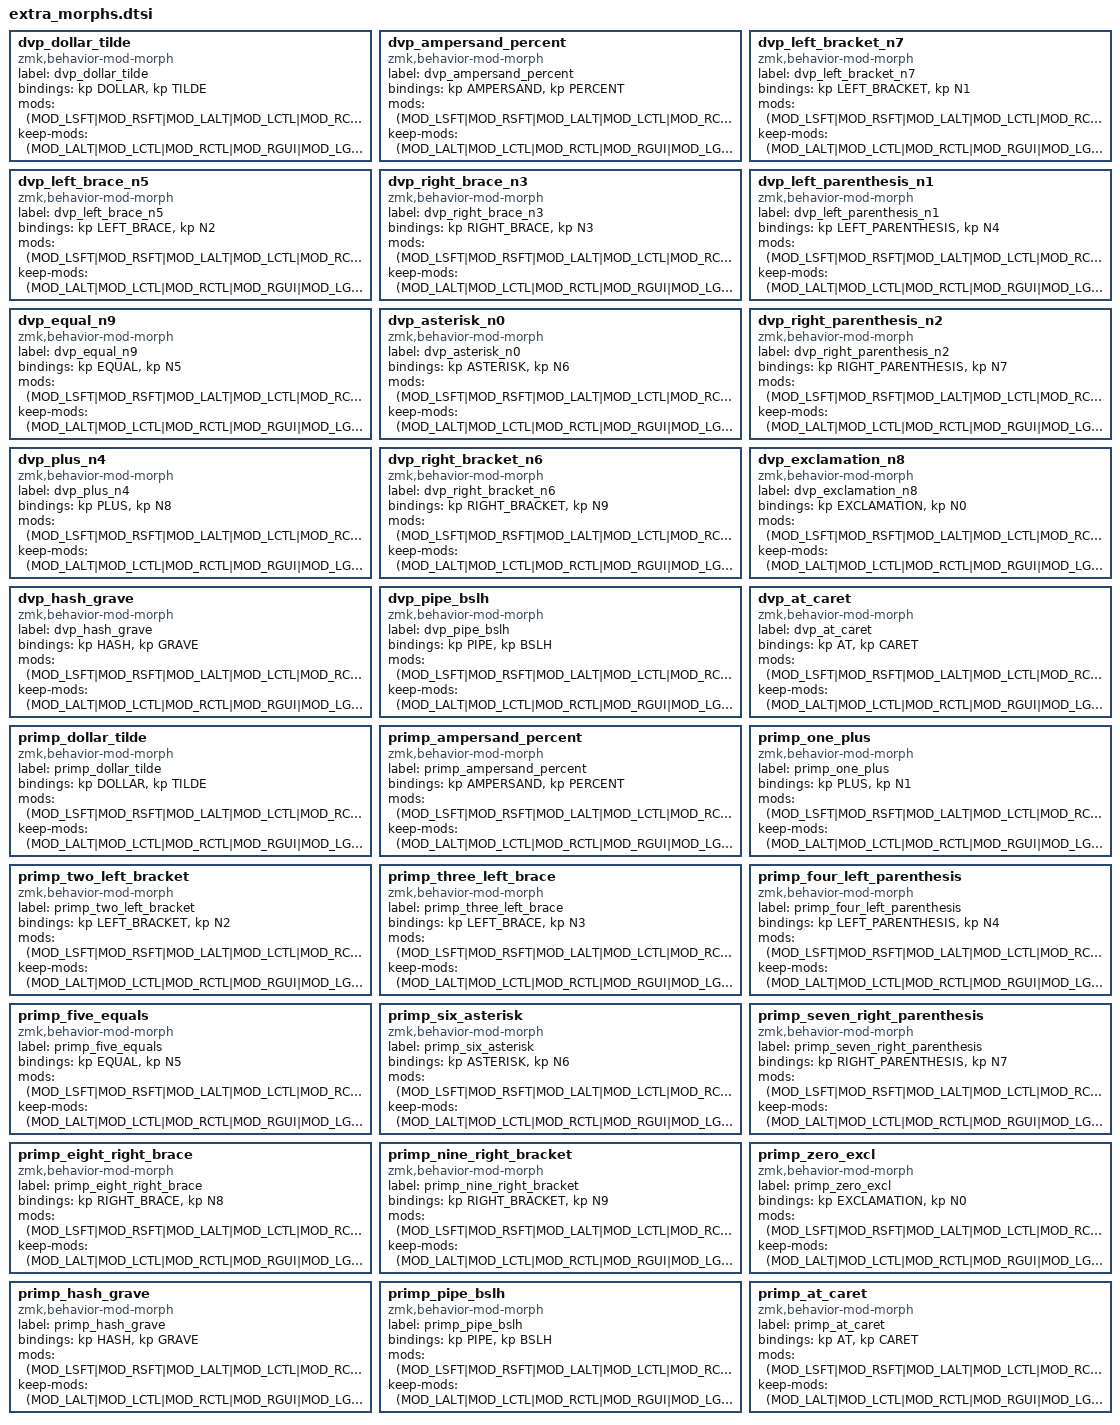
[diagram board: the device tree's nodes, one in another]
dvp_dollar_tilde: dvp_dollar_tilde {
    compatible = "zmk,behavior-mod-morph";
    label = "dvp_dollar_tilde";
    #binding-cells = <0>;
    bindings = <&kp DOLLAR>, <&kp TILDE>;
    mods = <(MOD_LSFT|MOD_RSFT|MOD_LALT|MOD_LCTL|MOD_RCTL|MOD_RGUI|MOD_LGUI)>;
    keep-mods = <(MOD_LALT|MOD_LCTL|MOD_RCTL|MOD_RGUI|MOD_LGUI)>;
};
dvp_ampersand_percent: dvp_ampersand_percent {
    compatible = "zmk,behavior-mod-morph";
    label = "dvp_ampersand_percent";
    #binding-cells = <0>;
    bindings = <&kp AMPERSAND>, <&kp PERCENT>;
    mods = <(MOD_LSFT|MOD_RSFT|MOD_LALT|MOD_LCTL|MOD_RCTL|MOD_RGUI|MOD_LGUI)>;
    keep-mods = <(MOD_LALT|MOD_LCTL|MOD_RCTL|MOD_RGUI|MOD_LGUI)>;
};
dvp_left_bracket_n7: dvp_left_bracket_n7 {
    compatible = "zmk,behavior-mod-morph";
    label = "dvp_left_bracket_n7";
    #binding-cells = <0>;
    bindings = <&kp LEFT_BRACKET>, <&kp N1>;
    mods = <(MOD_LSFT|MOD_RSFT|MOD_LALT|MOD_LCTL|MOD_RCTL|MOD_RGUI|MOD_LGUI)>;
    keep-mods = <(MOD_LALT|MOD_LCTL|MOD_RCTL|MOD_RGUI|MOD_LGUI)>;
};
dvp_left_brace_n5: dvp_left_brace_n5 {
    compatible = "zmk,behavior-mod-morph";
    label = "dvp_left_brace_n5";
    #binding-cells = <0>;
    bindings = <&kp LEFT_BRACE>, <&kp N2>;
    mods = <(MOD_LSFT|MOD_RSFT|MOD_LALT|MOD_LCTL|MOD_RCTL|MOD_RGUI|MOD_LGUI)>;
    keep-mods = <(MOD_LALT|MOD_LCTL|MOD_RCTL|MOD_RGUI|MOD_LGUI)>;
};
dvp_right_brace_n3: dvp_right_brace_n3 {
    compatible = "zmk,behavior-mod-morph";
    label = "dvp_right_brace_n3";
    #binding-cells = <0>;
    bindings = <&kp RIGHT_BRACE>, <&kp N3>;
    mods = <(MOD_LSFT|MOD_RSFT|MOD_LALT|MOD_LCTL|MOD_RCTL|MOD_RGUI|MOD_LGUI)>;
    keep-mods = <(MOD_LALT|MOD_LCTL|MOD_RCTL|MOD_RGUI|MOD_LGUI)>;
};
dvp_left_parenthesis_n1: dvp_left_parenthesis_n1 {
    compatible = "zmk,behavior-mod-morph";
    label = "dvp_left_parenthesis_n1";
    #binding-cells = <0>;
    bindings = <&kp LEFT_PARENTHESIS>, <&kp N4>;
    mods = <(MOD_LSFT|MOD_RSFT|MOD_LALT|MOD_LCTL|MOD_RCTL|MOD_RGUI|MOD_LGUI)>;
    keep-mods = <(MOD_LALT|MOD_LCTL|MOD_RCTL|MOD_RGUI|MOD_LGUI)>;
};
dvp_equal_n9: dvp_equal_n9 {
    compatible = "zmk,behavior-mod-morph";
    label = "dvp_equal_n9";
    #binding-cells = <0>;
    bindings = <&kp EQUAL>, <&kp N5>;
    mods = <(MOD_LSFT|MOD_RSFT|MOD_LALT|MOD_LCTL|MOD_RCTL|MOD_RGUI|MOD_LGUI)>;
    keep-mods = <(MOD_LALT|MOD_LCTL|MOD_RCTL|MOD_RGUI|MOD_LGUI)>;
};
dvp_asterisk_n0: dvp_asterisk_n0 {
    compatible = "zmk,behavior-mod-morph";
    label = "dvp_asterisk_n0";
    #binding-cells = <0>;
    bindings = <&kp ASTERISK>, <&kp N6>;
    mods = <(MOD_LSFT|MOD_RSFT|MOD_LALT|MOD_LCTL|MOD_RCTL|MOD_RGUI|MOD_LGUI)>;
    keep-mods = <(MOD_LALT|MOD_LCTL|MOD_RCTL|MOD_RGUI|MOD_LGUI)>;
};
dvp_right_parenthesis_n2: dvp_right_parenthesis_n2 {
    compatible = "zmk,behavior-mod-morph";
    label = "dvp_right_parenthesis_n2";
    #binding-cells = <0>;
    bindings = <&kp RIGHT_PARENTHESIS>, <&kp N7>;
    mods = <(MOD_LSFT|MOD_RSFT|MOD_LALT|MOD_LCTL|MOD_RCTL|MOD_RGUI|MOD_LGUI)>;
    keep-mods = <(MOD_LALT|MOD_LCTL|MOD_RCTL|MOD_RGUI|MOD_LGUI)>;
};
dvp_plus_n4: dvp_plus_n4 {
    compatible = "zmk,behavior-mod-morph";
    label = "dvp_plus_n4";
    #binding-cells = <0>;
    bindings = <&kp PLUS>, <&kp N8>;
    mods = <(MOD_LSFT|MOD_RSFT|MOD_LALT|MOD_LCTL|MOD_RCTL|MOD_RGUI|MOD_LGUI)>;
    keep-mods = <(MOD_LALT|MOD_LCTL|MOD_RCTL|MOD_RGUI|MOD_LGUI)>;
};
dvp_right_bracket_n6: dvp_right_bracket_n6 {
    compatible = "zmk,behavior-mod-morph";
    label = "dvp_right_bracket_n6";
    #binding-cells = <0>;
    bindings = <&kp RIGHT_BRACKET>, <&kp N9>;
    mods = <(MOD_LSFT|MOD_RSFT|MOD_LALT|MOD_LCTL|MOD_RCTL|MOD_RGUI|MOD_LGUI)>;
    keep-mods = <(MOD_LALT|MOD_LCTL|MOD_RCTL|MOD_RGUI|MOD_LGUI)>;
};
dvp_exclamation_n8: dvp_exclamation_n8 {
    compatible = "zmk,behavior-mod-morph";
    label = "dvp_exclamation_n8";
    #binding-cells = <0>;
    bindings = <&kp EXCLAMATION>, <&kp N0>;
    mods = <(MOD_LSFT|MOD_RSFT|MOD_LALT|MOD_LCTL|MOD_RCTL|MOD_RGUI|MOD_LGUI)>;
    keep-mods = <(MOD_LALT|MOD_LCTL|MOD_RCTL|MOD_RGUI|MOD_LGUI)>;
};
dvp_hash_grave: dvp_hash_grave {
    compatible = "zmk,behavior-mod-morph";
    label = "dvp_hash_grave";
    #binding-cells = <0>;
    bindings = <&kp HASH>, <&kp GRAVE>;
    mods = <(MOD_LSFT|MOD_RSFT|MOD_LALT|MOD_LCTL|MOD_RCTL|MOD_RGUI|MOD_LGUI)>;
    keep-mods = <(MOD_LALT|MOD_LCTL|MOD_RCTL|MOD_RGUI|MOD_LGUI)>;
};
dvp_pipe_bslh: dvp_pipe_bslh {
    compatible = "zmk,behavior-mod-morph";
    label = "dvp_pipe_bslh";
    #binding-cells = <0>;
    bindings = <&kp PIPE>, <&kp BSLH>;
    mods = <(MOD_LSFT|MOD_RSFT|MOD_LALT|MOD_LCTL|MOD_RCTL|MOD_RGUI|MOD_LGUI)>;
    keep-mods = <(MOD_LALT|MOD_LCTL|MOD_RCTL|MOD_RGUI|MOD_LGUI)>;
};
dvp_at_caret: dvp_at_caret {
    compatible = "zmk,behavior-mod-morph";
    label = "dvp_at_caret";
    #binding-cells = <0>;
    bindings = <&kp AT>, <&kp CARET>;
    mods = <(MOD_LSFT|MOD_RSFT|MOD_LALT|MOD_LCTL|MOD_RCTL|MOD_RGUI|MOD_LGUI)>;
    keep-mods = <(MOD_LALT|MOD_LCTL|MOD_RCTL|MOD_RGUI|MOD_LGUI)>;
};

primp_dollar_tilde: primp_dollar_tilde {
    compatible = "zmk,behavior-mod-morph";
    label = "primp_dollar_tilde";
    #binding-cells = <0>;
    bindings = <&kp DOLLAR>, <&kp TILDE>;
    mods = <(MOD_LSFT|MOD_RSFT|MOD_LALT|MOD_LCTL|MOD_RCTL|MOD_RGUI|MOD_LGUI)>;
    keep-mods = <(MOD_LALT|MOD_LCTL|MOD_RCTL|MOD_RGUI|MOD_LGUI)>;
};
primp_ampersand_percent: primp_ampersand_percent {
    compatible = "zmk,behavior-mod-morph";
    label = "primp_ampersand_percent";
    #binding-cells = <0>;
    bindings = <&kp AMPERSAND>, <&kp PERCENT>;
    mods = <(MOD_LSFT|MOD_RSFT|MOD_LALT|MOD_LCTL|MOD_RCTL|MOD_RGUI|MOD_LGUI)>;
    keep-mods = <(MOD_LALT|MOD_LCTL|MOD_RCTL|MOD_RGUI|MOD_LGUI)>;
};

primp_one_plus: primp_one_plus {
    compatible = "zmk,behavior-mod-morph";
    label = "primp_one_plus";
    #binding-cells = <0>;
    bindings = <&kp PLUS>, <&kp N1>;
    mods = <(MOD_LSFT|MOD_RSFT|MOD_LALT|MOD_LCTL|MOD_RCTL|MOD_RGUI|MOD_LGUI)>;
    keep-mods = <(MOD_LALT|MOD_LCTL|MOD_RCTL|MOD_RGUI|MOD_LGUI)>;
};

primp_two_left_bracket: primp_two_left_bracket {
    compatible = "zmk,behavior-mod-morph";
    label = "primp_two_left_bracket";
    #binding-cells = <0>;
    bindings = <&kp LEFT_BRACKET>, <&kp N2>;
    mods = <(MOD_LSFT|MOD_RSFT|MOD_LALT|MOD_LCTL|MOD_RCTL|MOD_RGUI|MOD_LGUI)>;
    keep-mods = <(MOD_LALT|MOD_LCTL|MOD_RCTL|MOD_RGUI|MOD_LGUI)>;
};

primp_three_left_brace: primp_three_left_brace {
    compatible = "zmk,behavior-mod-morph";
    label = "primp_three_left_brace";
    #binding-cells = <0>;
    bindings = <&kp LEFT_BRACE>, <&kp N3>;
    mods = <(MOD_LSFT|MOD_RSFT|MOD_LALT|MOD_LCTL|MOD_RCTL|MOD_RGUI|MOD_LGUI)>;
    keep-mods = <(MOD_LALT|MOD_LCTL|MOD_RCTL|MOD_RGUI|MOD_LGUI)>;
};

primp_four_left_parenthesis: primp_four_left_parenthesis {
    compatible = "zmk,behavior-mod-morph";
    label = "primp_four_left_parenthesis";
    #binding-cells = <0>;
    bindings = <&kp LEFT_PARENTHESIS>, <&kp N4>;
    mods = <(MOD_LSFT|MOD_RSFT|MOD_LALT|MOD_LCTL|MOD_RCTL|MOD_RGUI|MOD_LGUI)>;
    keep-mods = <(MOD_LALT|MOD_LCTL|MOD_RCTL|MOD_RGUI|MOD_LGUI)>;
};

primp_five_equals: primp_five_equals {
    compatible = "zmk,behavior-mod-morph";
    label = "primp_five_equals";
    #binding-cells = <0>;
    bindings = <&kp EQUAL>, <&kp N5>;
    mods = <(MOD_LSFT|MOD_RSFT|MOD_LALT|MOD_LCTL|MOD_RCTL|MOD_RGUI|MOD_LGUI)>;
    keep-mods = <(MOD_LALT|MOD_LCTL|MOD_RCTL|MOD_RGUI|MOD_LGUI)>;
};

primp_six_asterisk: primp_six_asterisk {
    compatible = "zmk,behavior-mod-morph";
    label = "primp_six_asterisk";
    #binding-cells = <0>;
    bindings = <&kp ASTERISK>, <&kp N6>;
    mods = <(MOD_LSFT|MOD_RSFT|MOD_LALT|MOD_LCTL|MOD_RCTL|MOD_RGUI|MOD_LGUI)>;
    keep-mods = <(MOD_LALT|MOD_LCTL|MOD_RCTL|MOD_RGUI|MOD_LGUI)>;
};

primp_seven_right_parenthesis: primp_seven_right_parenthesis {
    compatible = "zmk,behavior-mod-morph";
    label = "primp_seven_right_parenthesis";
    #binding-cells = <0>;
    bindings = <&kp RIGHT_PARENTHESIS>, <&kp N7>;
    mods = <(MOD_LSFT|MOD_RSFT|MOD_LALT|MOD_LCTL|MOD_RCTL|MOD_RGUI|MOD_LGUI)>;
    keep-mods = <(MOD_LALT|MOD_LCTL|MOD_RCTL|MOD_RGUI|MOD_LGUI)>;
};

primp_eight_right_brace: primp_eight_right_brace {
    compatible = "zmk,behavior-mod-morph";
    label = "primp_eight_right_brace";
    #binding-cells = <0>;
    bindings = <&kp RIGHT_BRACE>, <&kp N8>;
    mods = <(MOD_LSFT|MOD_RSFT|MOD_LALT|MOD_LCTL|MOD_RCTL|MOD_RGUI|MOD_LGUI)>;
    keep-mods = <(MOD_LALT|MOD_LCTL|MOD_RCTL|MOD_RGUI|MOD_LGUI)>;
};

primp_nine_right_bracket: primp_nine_right_bracket {
    compatible = "zmk,behavior-mod-morph";
    label = "primp_nine_right_bracket";
    #binding-cells = <0>;
    bindings = <&kp RIGHT_BRACKET>, <&kp N9>;
    mods = <(MOD_LSFT|MOD_RSFT|MOD_LALT|MOD_LCTL|MOD_RCTL|MOD_RGUI|MOD_LGUI)>;
    keep-mods = <(MOD_LALT|MOD_LCTL|MOD_RCTL|MOD_RGUI|MOD_LGUI)>;
};

primp_zero_excl: primp_zero_excl {
    compatible = "zmk,behavior-mod-morph";
    label = "primp_zero_excl";
    #binding-cells = <0>;
    bindings = <&kp EXCLAMATION>, <&kp N0>;
    mods = <(MOD_LSFT|MOD_RSFT|MOD_LALT|MOD_LCTL|MOD_RCTL|MOD_RGUI|MOD_LGUI)>;
    keep-mods = <(MOD_LALT|MOD_LCTL|MOD_RCTL|MOD_RGUI|MOD_LGUI)>;
};

primp_hash_grave: primp_hash_grave {
    compatible = "zmk,behavior-mod-morph";
    label = "primp_hash_grave";
    #binding-cells = <0>;
    bindings = <&kp HASH>, <&kp GRAVE>;
    mods = <(MOD_LSFT|MOD_RSFT|MOD_LALT|MOD_LCTL|MOD_RCTL|MOD_RGUI|MOD_LGUI)>;
    keep-mods = <(MOD_LALT|MOD_LCTL|MOD_RCTL|MOD_RGUI|MOD_LGUI)>;
};

primp_pipe_bslh: primp_pipe_bslh {
    compatible = "zmk,behavior-mod-morph";
    label = "primp_pipe_bslh";
    #binding-cells = <0>;
    bindings = <&kp PIPE>, <&kp BSLH>;
    mods = <(MOD_LSFT|MOD_RSFT|MOD_LALT|MOD_LCTL|MOD_RCTL|MOD_RGUI|MOD_LGUI)>;
    keep-mods = <(MOD_LALT|MOD_LCTL|MOD_RCTL|MOD_RGUI|MOD_LGUI)>;
};

primp_at_caret: primp_at_caret {
    compatible = "zmk,behavior-mod-morph";
    label = "primp_at_caret";
    #binding-cells = <0>;
    bindings = <&kp AT>, <&kp CARET>;
    mods = <(MOD_LSFT|MOD_RSFT|MOD_LALT|MOD_LCTL|MOD_RCTL|MOD_RGUI|MOD_LGUI)>;
    keep-mods = <(MOD_LALT|MOD_LCTL|MOD_RCTL|MOD_RGUI|MOD_LGUI)>;
};
